VERSION "SingleFrame2.dbc"

NS_ :

BS_:

BU_: TestNode TestNode2

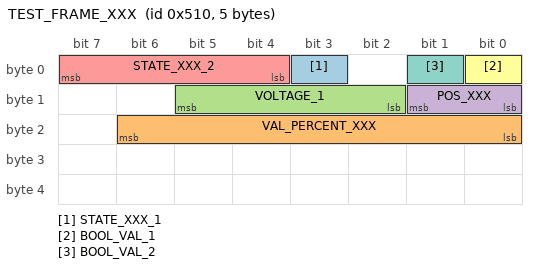
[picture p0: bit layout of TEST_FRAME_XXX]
BO_ 1296 TEST_FRAME_XXX: 5 TestNode
 SG_ STATE_XXX_1 : 3|1@1+ (1,0) [0|1] "bool" TestNode2
 SG_ VAL_PERCENT_XXX : 16|7@1+ (1,0) [0|100] "%" TestNode2
 SG_ VOLTAGE_1 : 10|4@1+ (1,0) [0|15] "V" TestNode2
 SG_ POS_XXX : 8|2@1+ (1,0) [0|3] "int" TestNode2
 SG_ STATE_XXX_2 : 4|4@1+ (1,0) [0|0] "" TestNode2
 SG_ BOOL_VAL_1 : 0|1@1+ (1,0) [0|0] "" TestNode2
 SG_ BOOL_VAL_2 : 1|1@1+ (1,0) [0|0] "" TestNode2
